AUTOSAR XML (schema 4-2-2)
package /Components
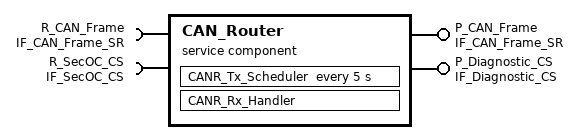
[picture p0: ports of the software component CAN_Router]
  service sw component type CAN_Router
    provide port P_CAN_Frame: provided-interface=IF_CAN_Frame_SR
    provide port P_Diagnostic_CS: provided-interface=IF_Diagnostic_CS
    require port R_CAN_Frame: required-interface=IF_CAN_Frame_SR
    require port R_SecOC_CS: required-interface=IF_SecOC_CS
    behavior CAN_Router_InternalBehavior
      data received event CANR_FrameRx: start-on-event=CANR_Rx_Handler
      init event CANR_InitEvent: start-on-event=CANR_Rx_Handler
      timing event CANR_TxSchedule: start-on-event=CANR_Tx_Scheduler, period=5
      runnable CANR_Rx_Handler: minimum-start-interval=1
        data-receive-point-by-values:
          access RX_CAN_Frame: accessed-variable=R_CAN_Frame.can_frame
        async call SecOC_Verify_Async: operation=R_SecOC_CS.Verify_Auth_Tag_Op, timeout=5
      runnable CANR_Tx_Scheduler: minimum-start-interval=5
        data-send-points:
          access TX_CAN_Frame: accessed-variable=P_CAN_Frame.can_frame
        sync call SecOC_Generate_Sync: operation=R_SecOC_CS.Generate_Auth_Tag_Op, timeout=2, called-from-within-exclusive-area=CANR_Tx_ExclusiveArea
